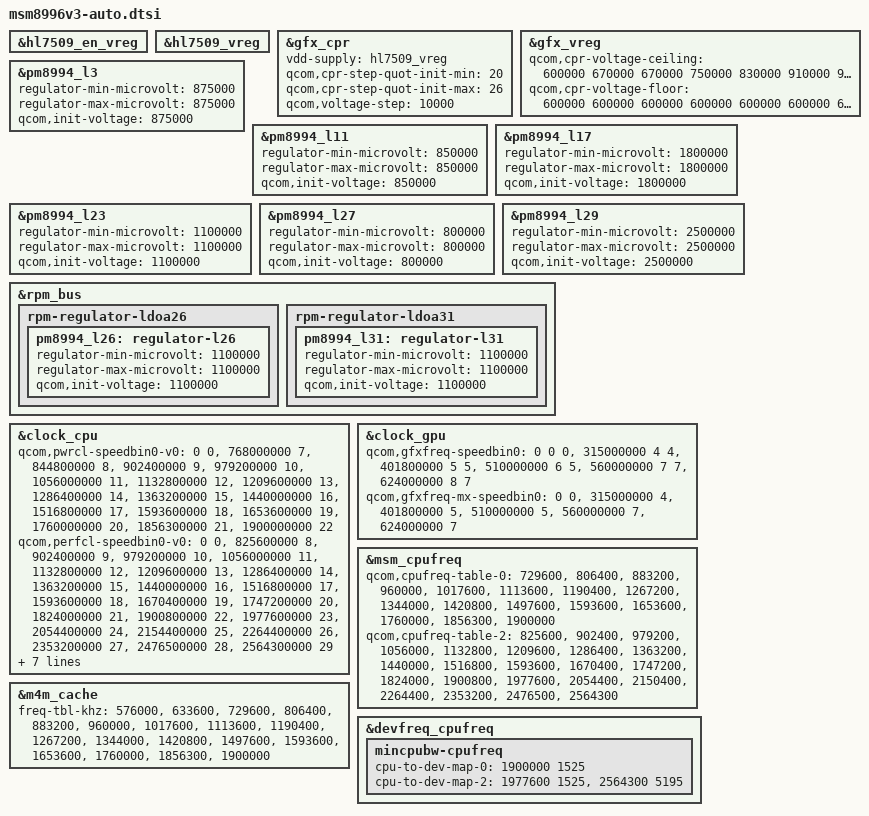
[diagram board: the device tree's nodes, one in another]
/* Copyright (c) 2016, The Linux Foundation. All rights reserved.
 *
 * This program is free software; you can redistribute it and/or modify
 * it under the terms of the GNU General Public License version 2 and
 * only version 2 as published by the Free Software Foundation.
 *
 * This program is distributed in the hope that it will be useful,
 * but WITHOUT ANY WARRANTY; without even the implied warranty of
 * MERCHANTABILITY or FITNESS FOR A PARTICULAR PURPOSE.  See the
 * GNU General Public License for more details.
 */

&hl7509_en_vreg {
	status = "ok";
};

&hl7509_vreg {
	status = "ok";
};

&gfx_cpr {
	vdd-supply = <&hl7509_vreg>;
	qcom,cpr-step-quot-init-min = <20>;
	qcom,cpr-step-quot-init-max = <26>;
	qcom,voltage-step = <10000>;
	/delete-property/ qcom,cpr-enable;
};

&gfx_vreg {
	qcom,cpr-voltage-ceiling =
		<600000  670000  670000  750000  830000
		 910000  960000 1020000>;
	qcom,cpr-voltage-floor =
		<600000  600000  600000  600000  600000
		 600000  600000  600000>;
};

&pm8994_l3 {
	regulator-min-microvolt = <875000>;
	regulator-max-microvolt = <875000>;
	qcom,init-voltage = <875000>;
};

&pm8994_l11 {
	regulator-min-microvolt = <850000>;
	regulator-max-microvolt = <850000>;
	qcom,init-voltage = <850000>;
};

&pm8994_l17 {
	regulator-min-microvolt = <1800000>;
	regulator-max-microvolt = <1800000>;
	qcom,init-voltage = <1800000>;
};

&pm8994_l23 {
	regulator-min-microvolt = <1100000>;
	regulator-max-microvolt = <1100000>;
	qcom,init-voltage = <1100000>;
};

&pm8994_l27 {
	regulator-min-microvolt = <800000>;
	regulator-max-microvolt = <800000>;
	qcom,init-voltage = <800000>;
};

&pm8994_l29 {
	regulator-min-microvolt = <2500000>;
	regulator-max-microvolt = <2500000>;
	qcom,init-voltage = <2500000>;
};

&rpm_bus {
	rpm-regulator-ldoa26 {
		/delete-node/ pm8994_l26_corner;
		/delete-node/ pm8994_l26_floor_corner;

		pm8994_l26: regulator-l26 {
			regulator-min-microvolt = <1100000>;
			regulator-max-microvolt = <1100000>;
			qcom,init-voltage = <1100000>;
			status = "okay";
		};
	};

	rpm-regulator-ldoa31 {
		status = "okay";
		pm8994_l31: regulator-l31 {
			regulator-min-microvolt = <1100000>;
			regulator-max-microvolt = <1100000>;
			qcom,init-voltage = <1100000>;
			status = "okay";
		};
	};
};

&clock_cpu {
	qcom,pwrcl-speedbin0-v0 =
		<          0  0 >,
		<  768000000  7 >,
		<  844800000  8 >,
		<  902400000  9 >,
		<  979200000 10 >,
		< 1056000000 11 >,
		< 1132800000 12 >,
		< 1209600000 13 >,
		< 1286400000 14 >,
		< 1363200000 15 >,
		< 1440000000 16 >,
		< 1516800000 17 >,
		< 1593600000 18 >,
		< 1653600000 19 >,
		< 1760000000 20 >,
		< 1856300000 21 >,
		< 1900000000 22 >;

	qcom,perfcl-speedbin0-v0 =
		<          0  0 >,
		<  825600000  8 >,
		<  902400000  9 >,
		<  979200000 10 >,
		< 1056000000 11 >,
		< 1132800000 12 >,
		< 1209600000 13 >,
		< 1286400000 14 >,
		< 1363200000 15 >,
		< 1440000000 16 >,
		< 1516800000 17 >,
		< 1593600000 18 >,
		< 1670400000 19 >,
		< 1747200000 20 >,
		< 1824000000 21 >,
		< 1900800000 22 >,
		< 1977600000 23 >,
		< 2054400000 24 >,
		< 2154400000 25 >,
		< 2264400000 26 >,
		< 2353200000 27 >,
		< 2476500000 28 >,
		< 2564300000 29 >;

	qcom,cbf-speedbin0-v0 =
		<          0  0 >,
		<  576000000  5 >,
		<  633600000  6 >,
		<  729600000  7 >,
		<  806400000  8 >,
		<  883200000  9 >,
		<  960000000 10 >,
		< 1017600000 11 >,
		< 1113600000 12 >,
		< 1190400000 13 >,
		< 1267200000 14 >,
		< 1344000000 15 >,
		< 1420800000 16 >,
		< 1497600000 17 >,
		< 1593600000 18 >,
		< 1653600000 19>,
		< 1760000000 20>,
		< 1856300000 21>,
		< 1900000000 22>;
};

&clock_gpu {
	qcom,gfxfreq-speedbin0 =
		<          0  0  0 >,
		<  315000000  4  4 >,
		<  401800000  5  5 >,
		<  510000000  6  5 >,
		<  560000000  7  7 >,
		<  624000000  8  7 >;

	qcom,gfxfreq-mx-speedbin0 =
		<          0  0 >,
		<  315000000  4 >,
		<  401800000  5 >,
		<  510000000  5 >,
		<  560000000  7 >,
		<  624000000  7 >;
};

&msm_cpufreq {
	qcom,cpufreq-table-0 =
		<  729600 >,
		<  806400 >,
		<  883200 >,
		<  960000 >,
		< 1017600 >,
		< 1113600 >,
		< 1190400 >,
		< 1267200 >,
		< 1344000 >,
		< 1420800 >,
		< 1497600 >,
		< 1593600 >,
		< 1653600 >,
		< 1760000 >,
		< 1856300 >,
		< 1900000 >;
	qcom,cpufreq-table-2 =
		<  825600 >,
		<  902400 >,
		<  979200 >,
		< 1056000 >,
		< 1132800 >,
		< 1209600 >,
		< 1286400 >,
		< 1363200 >,
		< 1440000 >,
		< 1516800 >,
		< 1593600 >,
		< 1670400 >,
		< 1747200 >,
		< 1824000 >,
		< 1900800 >,
		< 1977600 >,
		< 2054400 >,
		< 2150400 >,
		< 2264400 >,
		< 2353200 >, 
		< 2476500 >, 
		< 2564300 >;
};

&m4m_cache {
	freq-tbl-khz =
		<  576000 >,
		<  633600 >,
		<  729600 >,
		<  806400 >,
		<  883200 >,
		<  960000 >,
		< 1017600 >,
		< 1113600 >,
		< 1190400 >,
		< 1267200 >,
		< 1344000 >,
		< 1420800 >,
		< 1497600 >,
		< 1593600 >,
		< 1653600 >,
		< 1760000 >,
		< 1856300 >,
		< 1900000 >;
};
&devfreq_cpufreq {
	mincpubw-cpufreq {
		cpu-to-dev-map-0 =
			< 1900000 1525 >;
		cpu-to-dev-map-2 =
			< 1977600 1525 >,
			<  2564300  5195 >;
	};
};
